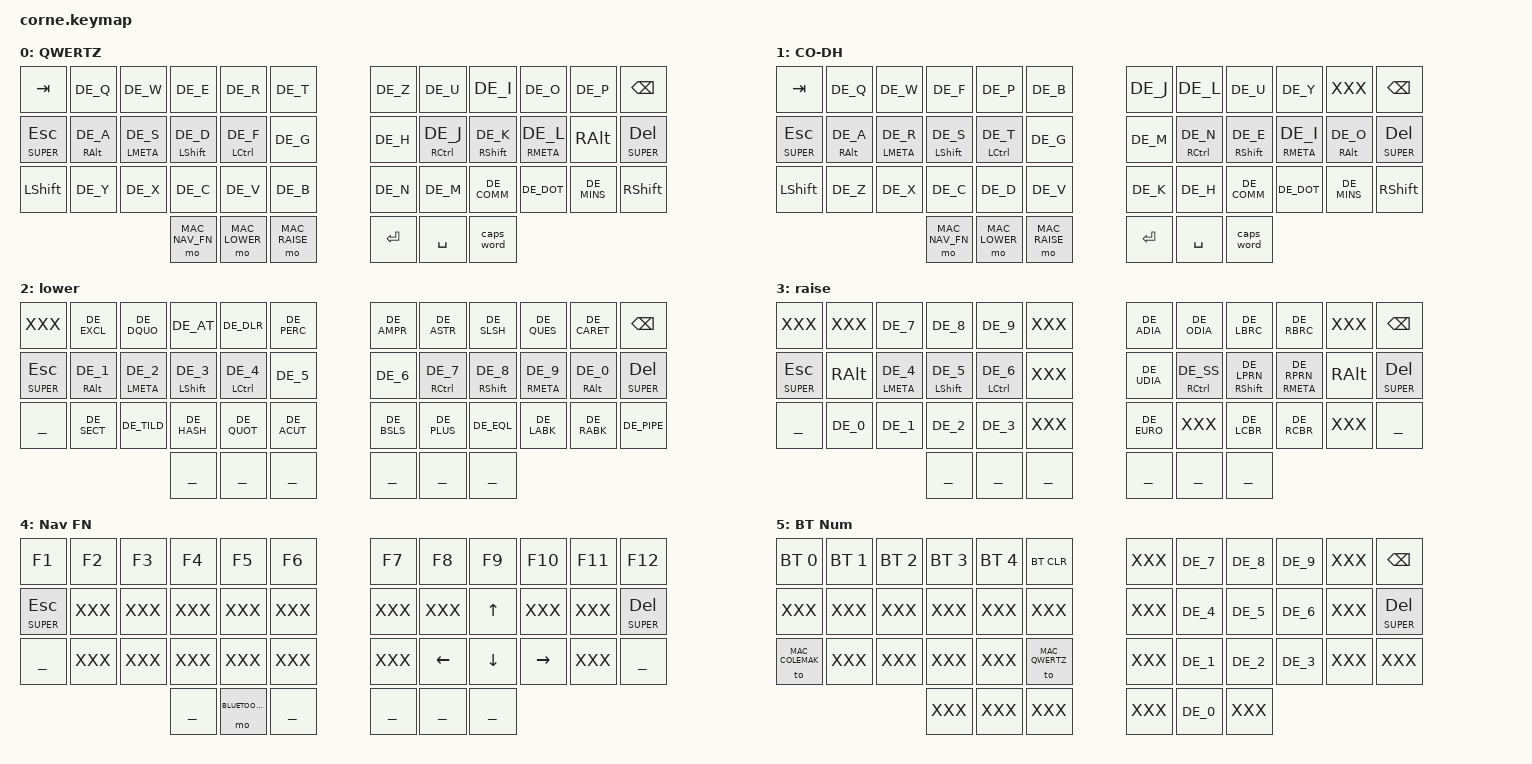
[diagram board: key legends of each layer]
/*
 * ZMK keymap for corne keyboard
*/

#include <behaviors.dtsi>
#include <dt-bindings/zmk/bt.h>
#include <dt-bindings/zmk/keys.h>

#include "42.h"       // 42 key Corne Keyboard
#include "keys_de.h"  // german keys

// Layers
#define MAC_QWERTZ 0
#define MAC_COLEMAK 1
#define MAC_LOWER 2
#define MAC_RAISE 3
#define MAC_NAV_FN 4
#define BLUETOOTH 5

// keys
#define KEYS_L LT0 LT1 LT2 LT3 LT4 LM0 LM1 LM2 LM3 LM4 LB0 LB1 LB2 LB3 LB4  // Left-hand keys.
#define KEYS_R RT0 RT1 RT2 RT3 RT4 RM0 RM1 RM2 RM3 RM4 RB0 RB1 RB2 RB3 RB4  // Right-hand keys.
#define THUMBS LH2 LH1 LH0 RH0 RH1 RH2                                      // Thumbs keys

// caps-word continue list
&caps_word {
  continue-list = <LSHIFT SPACE BACKSPACE DEL UNDERSCORE SLASH>;
};


/ {

  behaviors {
    hml: homerow_mods_left {
      compatible = "zmk,behavior-hold-tap";
      flavor = "balanced";
      #binding-cells = <2>;
      tapping-term-ms = <280>;
      quick-tap-ms = <175>;
      require-prior-idle-ms = <150>;
      bindings = <&kp>, <&kp>;
      hold-trigger-key-positions = <KEYS_R THUMBS>;
      hold-trigger-on-release;
    };

    hmr: homerow_mods_right {
      compatible = "zmk,behavior-hold-tap";
      flavor = "balanced";
      #binding-cells = <2>;
      tapping-term-ms = <280>;
      quick-tap-ms = <175>;
      require-prior-idle-ms = <100>;
      bindings = <&kp>, <&kp>;
      hold-trigger-key-positions = <KEYS_L THUMBS>;
      hold-trigger-on-release;
    };
  };

  keymap {
    compatible = "zmk,keymap";

    mac_qwertz_layer { // Layer 0 (MAC_QWERTZ)
      display-name = "QWERTZ";
      bindings = <
        //╭───────────────┬────────────────┬─────────────────┬─────────────────┬─────────────────┬───────────────╮ ╭───────────────────┬─────────────────┬─────────────────┬─────────────────┬──────────────┬─ ─────────────╮
            &kp TAB         &kp DE_Q         &kp DE_W          &kp DE_E          &kp DE_R          &kp DE_T          &kp DE_Z            &kp DE_U          &kp DE_I          &kp DE_O          &kp DE_P       &kp BSPC
        //├───────────────┼────────────────┼─────────────────┼─────────────────┼─────────────────┼───────────────┤ ├───────────────────┼─────────────────┼─────────────────┼─────────────────┼──────────────┼── ────────────┤
            &mt SUPER ESC   &hml RALT DE_A   &hml LMETA DE_S   &hml LSHFT DE_D   &hml LCTRL DE_F   &kp DE_G          &kp DE_H            &hmr RCTRL DE_J   &hmr RSHFT DE_K   &hmr RMETA DE_L   &kp RALT       &mt SUPER DEL
        //├───────────────┼────────────────┼─────────────────┼─────────────────┼─────────────────┼───────────────┤ ├───────────────────┼─────────────────┼─────────────────┼─────────────────┼──────────────┼─── ───────────┤
            &kp LSHFT       &kp DE_Y         &kp DE_X          &kp DE_C          &kp DE_V          &kp DE_B          &kp DE_N            &kp DE_M          &kp DE_COMM       &kp DE_DOT        &kp DE_MINS    &kp RSHFT
        //╰───────────────┴────────────────┴─────────────────┼─────────────────┼─────────────────┼───────────────┤ ├───────────────────┼─────────────────┼─────────────────┼─────────────────┴──────────────┴──── ──────────╯
                                                               &mo MAC_NAV_FN    &mo MAC_LOWER   &mo MAC_RAISE       &kp RET             &kp SPACE         &caps_word
        //                                                   ╰─────────────────┴─────────────────┴───────────────╯ ╰───────────────────┴─────────────────┴─────────────────╯
      >;
    };

    mac_colemak_dh { // Layer 1 (MAC_COLEMAK)
      display-name = "CO-DH";
      bindings = <
        //╭───────────────┬────────────────┬─────────────────┬─────────────────┬───────────────┬───────────────╮ ╭───────────────────┬─────────────────┬─────────────────┬─────────────────┬────────────────┬───────────────╮
            &kp TAB         &kp DE_Q         &kp DE_W          &kp DE_F          &kp DE_P        &kp DE_B          &kp DE_J            &kp DE_L          &kp DE_U          &kp DE_Y          XXX              &kp BSPC
        //├───────────────┼────────────────┼─────────────────┼─────────────────┼───────────────┼───────────────┤ ├───────────────────┼─────────────────┼─────────────────┼─────────────────┼────────────────┼───────────────┤
            &mt SUPER ESC   &hml RALT DE_A   &hml LMETA DE_R   &hml LSHFT DE_S   &hml LCTRL DE_T &kp DE_G          &kp DE_M            &hmr RCTRL DE_N   &hmr RSHFT DE_E   &hmr RMETA DE_I   &hmr RALT DE_O   &mt SUPER DEL
        //├───────────────┼────────────────┼─────────────────┼─────────────────┼───────────────┼───────────────┤ ├───────────────────┼─────────────────┼─────────────────┼─────────────────┼────────────────┼───────────────┤
            &kp LSHFT       &kp DE_Z         &kp DE_X          &kp DE_C          &kp DE_D        &kp DE_V          &kp DE_K            &kp DE_H          &kp DE_COMM       &kp DE_DOT        &kp DE_MINS      &kp RSHFT
        //╰───────────────┴────────────────┴─────────────────┼─────────────────┼───────────────┼───────────────┤ ├───────────────────┼─────────────────┼─────────────────┼─────────────────┴────────────────┴───────────────╯
                                                               &mo MAC_NAV_FN    &mo MAC_LOWER   &mo MAC_RAISE     &kp RET             &kp SPACE         &caps_word
        //                                                   ╰─────────────────┴───────────────┴───────────────╯ ╰───────────────────┴─────────────────┴─────────────────╯
      >;
    };

    mac_lower_layer { // Layer 2 (MAC_LOWER)
      display-name = "lower";
      bindings = <
        //╭───────────────┬────────────────┬─────────────────┬─────────────────┬─────────────────┬───────────────╮ ╭───────────────────┬─────────────────┬─────────────────┬─────────────────┬────────────────┬───────────────╮
            XXX             &kp DE_EXCL      &kp DE_DQUO       &kp DE_AT         &kp DE_DLR        &kp DE_PERC       &kp DE_AMPR         &kp DE_ASTR       &kp DE_SLSH       &kp DE_QUES       &kp DE_CARET     &kp BSPC
        //├───────────────┼────────────────┼─────────────────┼─────────────────┼─────────────────┼───────────────┤ ├───────────────────┼─────────────────┼─────────────────┼─────────────────┼────────────────┼───────────────┤
            &mt SUPER ESC   &hml RALT DE_1   &hml LMETA DE_2   &hml LSHFT DE_3   &hml LCTRL DE_4   &kp DE_5          &kp DE_6            &hmr RCTRL DE_7   &hmr RSHFT DE_8   &hmr RMETA DE_9   &hmr RALT DE_0   &mt SUPER DEL
        //├───────────────┼────────────────┼─────────────────┼─────────────────┼─────────────────┼───────────────┤ ├───────────────────┼─────────────────┼─────────────────┼─────────────────┼────────────────┼───────────────┤
            ___             &kp DE_SECT      &kp DE_TILD       &kp DE_HASH       &kp DE_QUOT       &kp DE_ACUT       &kp DE_BSLS         &kp DE_PLUS       &kp DE_EQL        &kp DE_LABK       &kp DE_RABK      &kp DE_PIPE
        //╰───────────────┴────────────────┴─────────────────┼─────────────────┼─────────────────┼───────────────┤ ├───────────────────┼─────────────────┼─────────────────┼─────────────────┴────────────────┴───────────────╯
                                                               ___               ___               ___               ___                 ___               ___
        //                                                   ╰─────────────────┴─────────────────┴───────────────╯ ╰───────────────────┴─────────────────┴─────────────────╯
      >;
    };

    mac_raise_layer { // Layer 3 (MAC_RAISE)
      display-name = "raise";
      bindings = <
        //╭───────────────┬───────────────┬─────────────────┬─────────────────┬─────────────────┬───────────────╮ ╭───────────────────┬──────────────────┬────────────────────┬────────────────────┬──────────────┬───────────────╮
            XXX             XXX             &kp DE_7          &kp DE_8          &kp DE_9          XXX               &kp DE_ADIA         &kp DE_ODIA        &kp DE_LBRC          &kp DE_RBRC          XXX            &kp BSPC
        //├───────────────┼───────────────┼─────────────────┼─────────────────┼─────────────────┼───────────────┤ ├───────────────────┼──────────────────┼────────────────────┼────────────────────┼──────────────┼───────────────┤
            &mt SUPER ESC   &kp RALT        &hml LMETA DE_4   &hml LSHFT DE_5   &hml LCTRL DE_6   XXX               &kp DE_UDIA         &hmr RCTRL DE_SS   &hmr RSHFT DE_LPRN   &hmr RMETA DE_RPRN   &kp RALT       &mt SUPER DEL
        //├───────────────┼───────────────┼─────────────────┼─────────────────┼─────────────────┼───────────────┤ ├───────────────────┼──────────────────┼────────────────────┼────────────────────┼──────────────┼───────────────┤
            ___             &kp DE_0        &kp DE_1          &kp DE_2          &kp DE_3          XXX               &kp DE_EURO         XXX                &kp DE_LCBR          &kp DE_RCBR          XXX            ___
        //╰───────────────┴───────────────┴─────────────────┼─────────────────┼─────────────────┼───────────────┤ ├───────────────────┼──────────────────┼────────────────────┼────────────────────┴──────────────┴───────────────╯
                                                              ___               ___               ___               ___                 ___                ___
        //                                                  ╰─────────────────┴─────────────────┴───────────────╯ ╰───────────────────┴──────────────────┴────────────────────╯
      >;
    };

    mac_nav_fn { // Layer 4 (MAC_NAV_FN)
      display-name = "Nav FN";
      bindings = <
        //╭───────────────┬───────────────┬───────────────┬────────────────┬───────────────┬───────────────╮ ╭───────────────────┬───────────────┬────────────────┬─────────────────┬──────────────┬───────────────╮
            &kp F1          &kp F2          &kp F3          &kp F4           &kp F5          &kp F6            &kp F7              &kp F8          &kp F9           &kp F10           &kp F11        &kp F12
        //├───────────────┼───────────────┼───────────────┼────────────────┼───────────────┼───────────────┤ ├───────────────────┼───────────────┼────────────────┼─────────────────┼──────────────┼───────────────┤
            &mt SUPER ESC   XXX             XXX             XXX              XXX             XXX               XXX                 XXX             &kp UP_ARROW     XXX               XXX            &mt SUPER DEL
        //├───────────────┼───────────────┼───────────────┼────────────────┼───────────────┼───────────────┤ ├───────────────────┼───────────────┼────────────────┼─────────────────┼──────────────┼───────────────┤
            ___             XXX             XXX             XXX              XXX             XXX               XXX                 &kp LEFT_ARROW  &kp DOWN_ARROW   &kp RIGHT_ARROW   XXX            ___
        //╰───────────────┴───────────────┴───────────────┼────────────────┼───────────────┼───────────────┤ ├───────────────────┼───────────────┼────────────────┼─────────────────┴──────────────┴───────────────╯
                                                            ___              &mo BLUETOOTH   ___              ___                 ___             ___
        //                                                ╰────────────────┴───────────────┴───────────────╯ ╰───────────────────┴───────────────┴────────────────╯
      >;
    };

    bluetooth { // Layer 5 (BLUETOOTH)
      display-name = "BT Num";
      bindings = <
        //╭─────────────────┬─────────────────┬──────────────┬──────────────┬────────────────┬────────────────╮ ╭─────────────────┬────────────┬────────────┬────────────┬───────────┬───────────────╮
            &bt BT_SEL 0      &bt BT_SEL 1      &bt BT_SEL 2   &bt BT_SEL 3   &bt BT_SEL 4     &bt BT_CLR         XXX               &kp DE_7     &kp DE_8     &kp DE_9     XXX         &kp BSPC
        //├─────────────────┼─────────────────┼──────────────┼──────────────┼────────────────┼────────────────┤ ├─────────────────┼────────────┼────────────┼────────────┼───────────┼───────────────┤
            XXX               XXX               XXX            XXX            XXX              XXX                XXX               &kp DE_4     &kp DE_5     &kp DE_6     XXX         &mt SUPER DEL  
        //├─────────────────┼─────────────────┼──────────────┼──────────────┼────────────────┼────────────────┤ ├─────────────────┼────────────┼────────────┼────────────┼───────────┼───────────────┤
            &to MAC_COLEMAK   XXX               XXX            XXX            XXX              &to MAC_QWERTZ     XXX               &kp DE_1     &kp DE_2     &kp DE_3     XXX         XXX
        //╰─────────────────┴─────────────────┴──────────────┼──────────────┼────────────────┼────────────────┤ ├─────────────────┼────────────┼────────────┼────────────┴───────────┴───────────────╯
                                                               XXX            XXX              XXX                XXX               &kp DE_0     XXX   
        //                                                   ╰──────────────┴────────────────┴────────────────╯ ╰─────────────────┴────────────┴────────────╯
      >;
    };

  };
};

